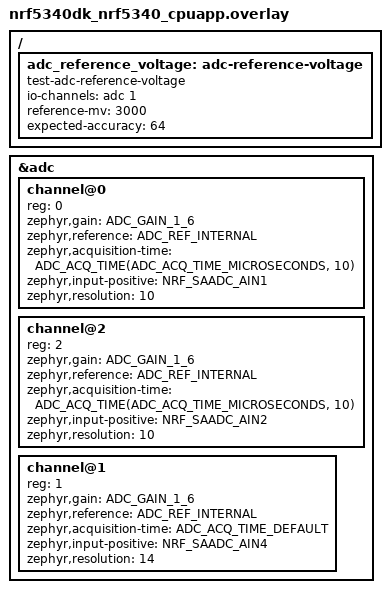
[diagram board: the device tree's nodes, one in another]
/*
 * SPDX-License-Identifier: Apache-2.0
 *
 * Copyright (c) 2026 Nordic Semiconductor ASA
 */

&adc {
	#address-cells = <1>;
	#size-cells = <0>;

	channel@0 {
		reg = <0>;
		zephyr,gain = "ADC_GAIN_1_6";
		zephyr,reference = "ADC_REF_INTERNAL";
		zephyr,acquisition-time = <ADC_ACQ_TIME(ADC_ACQ_TIME_MICROSECONDS, 10)>;
		zephyr,input-positive = <NRF_SAADC_AIN1>;
		zephyr,resolution = <10>;
	};

	channel@2 {
		reg = <2>;
		zephyr,gain = "ADC_GAIN_1_6";
		zephyr,reference = "ADC_REF_INTERNAL";
		zephyr,acquisition-time = <ADC_ACQ_TIME(ADC_ACQ_TIME_MICROSECONDS, 10)>;
		zephyr,input-positive = <NRF_SAADC_AIN2>;
		zephyr,resolution = <10>;
	};

	channel@1 {
		reg = <1>;
		zephyr,gain = "ADC_GAIN_1_6";
		zephyr,reference = "ADC_REF_INTERNAL";
		zephyr,acquisition-time = <ADC_ACQ_TIME_DEFAULT>;
		zephyr,input-positive = <NRF_SAADC_AIN4>; /* P0.25 */
		zephyr,resolution = <14>;
	};
};

/ {
	adc_reference_voltage: adc-reference-voltage {
		compatible = "test-adc-reference-voltage";
		io-channels = <&adc 1>;
		reference-mv = <3000>;
		expected-accuracy = <64>;
	};
};
